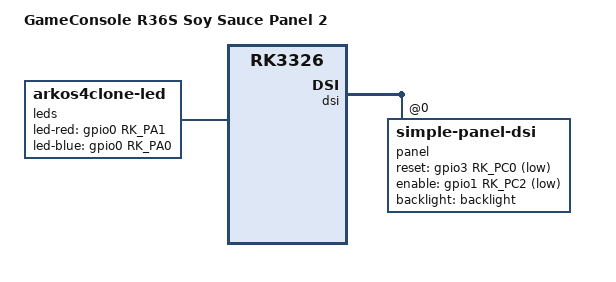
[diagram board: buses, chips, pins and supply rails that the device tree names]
// SPDX-License-Identifier: (GPL-2.0+ OR MIT)
/*
* Copyright (c) 2026 kk&lcdyk
*
* R36S 酱油 Panel 2
*
*/

/dts-v1/;
#include "rk3326-r36s-sauce.dtsi"

/ {
	model = "GameConsole R36S Soy Sauce Panel 2";
	compatible = "rockchip,rk3326-r36s-sauce-panel2-linux", "rockchip,rk3326";

	leds: arkos4clone-leds {
		compatible = "arkos4clone-led";
		
		led-red = <&gpio0 RK_PA1 GPIO_ACTIVE_HIGH>;
		led-blue = <&gpio0 RK_PA0 GPIO_ACTIVE_HIGH>;
	};
};

&dsi {
	status = "okay";
	
	panel@0 {
		compatible = "simple-panel-dsi";
		reg = <0>;
		/* pwm1 backlight */
		backlight = <&backlight>;
		/* LCD reset gpio GPIO3.B7 */
		reset-gpios = <&gpio3 RK_PC0 GPIO_ACTIVE_LOW>;
		/* power-supply-gpio GPIO0.B5  */
		enable-gpios = <&gpio1 RK_PC2 GPIO_ACTIVE_LOW>;
		prepare-delay-ms = <100>;
		reset-delay-ms = <50>;
		init-delay-ms = <20>;
		enable-delay-ms = <200>;
		disable-delay-ms = <50>;
		unprepare-delay-ms = <250>;
		width-mm = <71>;
		height-mm = <71>;
		dsi,flags  = <(MIPI_DSI_MODE_VIDEO |
		MIPI_DSI_MODE_VIDEO_BURST |
		MIPI_DSI_MODE_LPM |
		MIPI_DSI_MODE_EOT_PACKET)>;
		dsi,format = <MIPI_DSI_FMT_RGB888>;
		dsi,lanes = <4>;
		panel-init-sequence = [05 96 01 11 05 32 01 29];
		panel-exit-sequence = [05 14 01 28 05 0a 01 10];
		
		display-timings {
			native-mode = <&timing0>;

			// 40.00MHz / (640+120+120+120)×(480+17+5+13) = 1000×515 = 77.67 Hz
			timing0: original {
				clock-frequency = <40000000>;
				hactive = <640>;
				vactive = <480>;
				hback-porch = <120>;
				hfront-porch = <120>;
				vback-porch = <13>;
				vfront-porch = <17>;
				hsync-len = <120>;
				vsync-len = <5>;
				hsync-active = <0>;
				vsync-active = <0>;
				de-active = <0>;
				pixelclk-active = <0>;
			};
			
			// 40.00MHz / (640+120+120+120)×(480+80+7+100) = 1000×667 = 59.97 Hz
			timing1: adjust {
				clock-frequency = <40000000>;
				hactive = <640>;
				vactive = <480>;
				hfront-porch = <120>;
				hsync-len = <120>;
				hback-porch = <120>;
				vfront-porch = <80>;
				vsync-len = <7>;
				vback-porch = <100>;
				hsync-active = <0>;
				vsync-active = <0>;
				de-active = <0>;
				pixelclk-active = <0>;
			};
		};
	};
};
